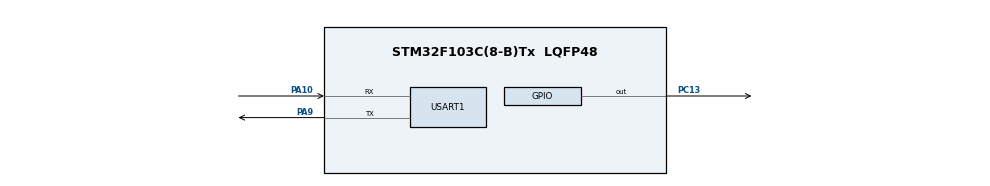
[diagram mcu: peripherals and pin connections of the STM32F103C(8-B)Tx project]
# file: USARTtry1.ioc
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Mcu.Family=STM32F1
RCC.APB2Freq_Value=8000000
PA10.Mode=Asynchronous
PA14.Mode=Serial_Wire
PC13-TAMPER-RTC.Signal=GPIO_Output
PA13.Mode=Serial_Wire
Mcu.Name=STM32F103C(8-B)Tx
Mcu.Package=LQFP48
ProjectManager.StackSize=0x400
PA13.Signal=SYS_JTMS-SWDIO
USART1.VirtualMode=VM_ASYNC
PA9.Mode=Asynchronous
PA10.Signal=USART1_RX
PA14.Signal=SYS_JTCK-SWCLK
ProjectManager.HeapSize=0x200
ProjectManager.TargetToolchain=TrueSTUDIO
NVIC.PriorityGroup=NVIC_PRIORITYGROUP_4
PA9.Signal=USART1_TX
RCC.APB1Freq_Value=8000000
board=custom

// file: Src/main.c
/* USER CODE BEGIN Header */
/**
  ******************************************************************************
  * @file           : main.c
  * @brief          : Main program body
  ******************************************************************************
  * @attention
  *
  * <h2><center>&copy; Copyright (c) 2020 STMicroelectronics.
  * All rights reserved.</center></h2>
  *
  * This software component is licensed by ST under BSD 3-Clause license,
  * the "License"; You may not use this file except in compliance with the
  * License. You may obtain a copy of the License at:
  *                        opensource.org/licenses/BSD-3-Clause
  *
  ******************************************************************************
  */
/* USER CODE END Header */

#include "main.h"

/* USER CODE BEGIN Includes */
#include<string.h>
#include<stdio.h>
#include "variabl3s.h"
/* USER CODE END Includes */

UART_HandleTypeDef huart1;

void SystemClock_Config(void);
static void MX_GPIO_Init(void);
static void MX_USART1_UART_Init(void);

int main(void)
{
  /* USER CODE BEGIN 1 */
	char print[20];
  /* USER CODE END 1 */

  /* MCU Configuration--------------------------------------------------------*/

  /* Reset of all peripherals, Initializes the Flash interface and the Systick. */
  HAL_Init();

  /* Configure the system clock */
  SystemClock_Config();

  /* Initialize all configured peripherals */
  MX_GPIO_Init();
  MX_USART1_UART_Init();

  /* Infinite loop */
  /* USER CODE BEGIN WHILE */
  while (1)
  {
	  increment(1);
	  //Convert Integer to String
	  sprintf(print,"%d",count);
	  strcat(print,"\r\n\0");
	  HAL_UART_Transmit(&huart1, (uint8_t *) print, strlen(print) , HAL_MAX_DELAY);
    /* USER CODE END WHILE */

  }
}

void SystemClock_Config(void)
{
  RCC_OscInitTypeDef RCC_OscInitStruct = {0};
  RCC_ClkInitTypeDef RCC_ClkInitStruct = {0};

  /** Initializes the CPU, AHB and APB busses clocks
  */
  RCC_OscInitStruct.OscillatorType = RCC_OSCILLATORTYPE_HSI;
  RCC_OscInitStruct.HSIState = RCC_HSI_ON;
  RCC_OscInitStruct.HSICalibrationValue = RCC_HSICALIBRATION_DEFAULT;
  RCC_OscInitStruct.PLL.PLLState = RCC_PLL_NONE;
  if (HAL_RCC_OscConfig(&RCC_OscInitStruct) != HAL_OK)
  {
    Error_Handler();
  }
  /** Initializes the CPU, AHB and APB busses clocks
  */
  RCC_ClkInitStruct.ClockType = RCC_CLOCKTYPE_HCLK|RCC_CLOCKTYPE_SYSCLK
                              |RCC_CLOCKTYPE_PCLK1|RCC_CLOCKTYPE_PCLK2;
  RCC_ClkInitStruct.SYSCLKSource = RCC_SYSCLKSOURCE_HSI;
  RCC_ClkInitStruct.AHBCLKDivider = RCC_SYSCLK_DIV1;
  RCC_ClkInitStruct.APB1CLKDivider = RCC_HCLK_DIV1;
  RCC_ClkInitStruct.APB2CLKDivider = RCC_HCLK_DIV1;

  if (HAL_RCC_ClockConfig(&RCC_ClkInitStruct, FLASH_LATENCY_0) != HAL_OK)
  {
    Error_Handler();
  }
}

static void MX_USART1_UART_Init(void)
{

  huart1.Instance = USART1;
  huart1.Init.BaudRate = 9600;
  huart1.Init.WordLength = UART_WORDLENGTH_8B;
  huart1.Init.StopBits = UART_STOPBITS_1;
  huart1.Init.Parity = UART_PARITY_NONE;
  huart1.Init.Mode = UART_MODE_TX_RX;
  huart1.Init.HwFlowCtl = UART_HWCONTROL_NONE;
  huart1.Init.OverSampling = UART_OVERSAMPLING_16;
  if (HAL_UART_Init(&huart1) != HAL_OK)
  {
    Error_Handler();
  }

}

static void MX_GPIO_Init(void)
{
  GPIO_InitTypeDef GPIO_InitStruct = {0};

  /* GPIO Ports Clock Enable */
  __HAL_RCC_GPIOC_CLK_ENABLE();
  __HAL_RCC_GPIOA_CLK_ENABLE();

  /*Configure GPIO pin Output Level */
  HAL_GPIO_WritePin(GPIOC, GPIO_PIN_13, GPIO_PIN_RESET);

  /*Configure GPIO pin : PC13 */
  GPIO_InitStruct.Pin = GPIO_PIN_13;
  GPIO_InitStruct.Mode = GPIO_MODE_OUTPUT_PP;
  GPIO_InitStruct.Pull = GPIO_NOPULL;
  GPIO_InitStruct.Speed = GPIO_SPEED_FREQ_LOW;
  HAL_GPIO_Init(GPIOC, &GPIO_InitStruct);

}

void Error_Handler(void)
{
}

/************************ (C) COPYRIGHT STMicroelectronics *****END OF FILE****/
